# WB32F10x register map
File version: 1.2
CPU: CM3 r2p0, little endian, MPU, no FPU, 4 interrupt priority bits
Registers are 32-bit, read-write, reset 0x0 unless marked. A register's access mark holds for its fields unless they carry their own. Offsets are from the block's base; lines under a group give offsets from that group; [hi:lo] are bit positions; {n}, {i} and the like mark numbered series; 'fields as' and 'values as' point back to an identical list; <NAME> marks a mode.

## Memory map
0x40000000 GPIOA size 0x400 — General-purpose and alternate-function I/O
0x40000400 GPIOB size 0x400 — General-purpose and alternate-function I/O
0x40000800 GPIOC size 0x400 — General-purpose and alternate-function I/O
0x40000C00 GPIOD size 0x400 — General-purpose and alternate-function I/O
0x40001400 AFIO size 0x400 — AFIO registers
0x40001800 EXTI size 0x400 — Interrupt/event controller
0x4000B800 RNG size 0x400 — Random Number Generator
0x40010000 PWR size 0x400 — Power control
0x40010400 ANCTL size 0x400 — Analog control
0x40010C00 RCC size 0x400 — Reset and Clock Control
0x40014800 CRC size 0x400 — Cyclic Redundancy Check
0x40015C00 BKP size 0x400 — Backup registers
0x40016400 SYS size 0x400 — System configuration

## CRC — Cyclic Redundancy Check
Base 0x40014800
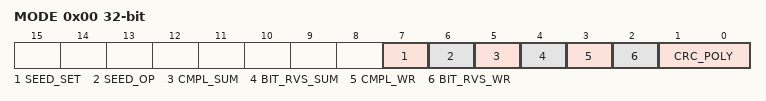
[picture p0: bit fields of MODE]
0x00 MODE — CRC mode register
  [7] SEED_SET — Load seed to CRC generator
  [6] SEED_OP — CRC seed option set
  [5] CMPL_SUM — Select one's complement for CRC_SUM
  [4] BIT_RVS_SUM — Select bit order revers for CRC_SUM
  [3] CMPL_WR — Select one's complement for CRC_WR_DATA
  [2] BIT_RVS_WR — Select bit order for CRC_WR_DATA
  [1:0] CRC_POLY — Select CRC polynomial field
0x04 SEED reset 0xFFFF — CRC seed register
  [31:0] SEED — CRC seed value
0x08 SUM ro reset 0xFFFF — CRC checksum register
  [31:0] SUM — CRC checksum
0x08 WDATA write — CRC data register
  [31:0] WDATA — CRC data

## RNG — Random Number Generator
Base 0x4000B800
0x00 RAND ro — Random number generator register
  [7:0] RAND — Generated 8-bit random number
0x04 STOP — RNG STOP register
  [0] STOP — RNG STOP control
0x08 REC ro — RNG Record register
  [7:0] REC — The random data being read last time

## PWR — Power control
Base 0x40010000
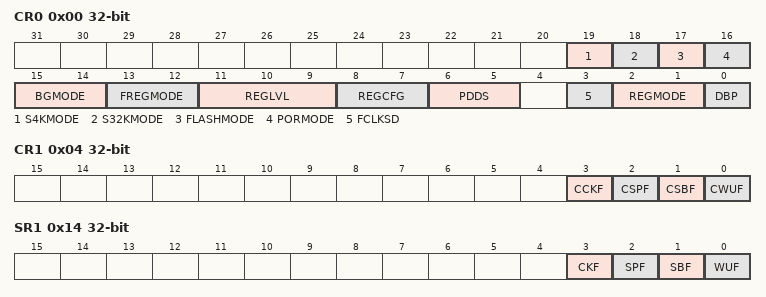
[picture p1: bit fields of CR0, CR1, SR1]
0x00 CR0 — Power control register 0
  [19] S4KMODE — Configure the state of 4K SRAM when it enters stop mode
  [18] S32KMODE — Configure the state of 32K SRAM when it enters stop mode
  [17] FLASHMODE — Configure the state of the flash memory when it enters stop mode
  [16] PORMODE — Configure the status of the POR BG when it enters stop mode
  [15:14] BGMODE — Configure the status of the bandgap when it enters the stop mode
  [13:12] FREGMODE — Configure the state of the flash regulator when it enters stop mode
  [11:9] REGLVL — Configure the step value of the voltage regulator
  [8:7] REGCFG — Configure the voltage change direction of the voltage regulator
  [6:5] PDDS — Configure the working state of the device when the Cortex ® -M3 enters deep sleep mode
  [3] FCLKSD — Reduce the frequency of Cortex ® -M3 FCLK
  [2:1] REGMODE — Configure the state of the voltage regulator when it enters stop mode
  [0] DBP — Disable the write protection for backup domain registers
0x04 CR1 write — Control register 1
  [3] CCKF — Clear CKF flag bit
  [2] CSPF — Clear SPF flag bit
  [1] CSBF — Clear SBF flag bit
  [0] CWUF — Clear WUF flag bit
0x08 CR2 — Control register 2
  [0] EWUP — Enable WKUP pin
0x10 SR0 ro — Status register 0
  [0] PVD0 — PVD output
0x14 SR1 ro — Status register 1
  [3] CKF — CKF Flag
  [2] SPF — Stop flag
  [1] SBF — Standby flag
  [0] WUF — Wakeup flag
0x18 GPREG0 — General purpose register 0
0x1C GPREG1 — General purpose register 1
0x20 CFGR reset 0x3BE — Configuration register
  [12:0] LPCFG — Configure the time to enter and exit low power mode
0x28 ANAKEY1 — Analog enable register 1
0x2C ANAKEY2 — Analog enable register 2

## Licence text in the file
ARM Limited (ARM) is supplying this software for use with Cortex-M processor based microcontroller, but can be equally used for other suitable processor architectures. This file can be freely distributed. Modifications to this file shall be clearly marked. THIS SOFTWARE IS PROVIDED "AS IS". NO WARRANTIES, WHETHER EXPRESS, IMPLIED OR STATUTORY, INCLUDING, BUT NOT LIMITED TO, IMPLIED WARRANTIES OF MERCHANTABILITY AND FITNESS FOR A PARTICULAR PURPOSE APPLY TO THIS SOFTWARE. ARM SHALL NOT, IN ANY CIRCUMSTANCES, BE LIABLE FOR SPECIAL, INCIDENTAL, OR CONSEQUENTIAL DAMAGES, FOR ANY REASON WHATSOEVER.
